# RS14100 register map
File version: 1.0
CPU: CM4 r0p1, little endian, MPU, FPU, 4 interrupt priority bits
Registers are 32-bit, read-write, reset 0x0 unless marked. A register's access mark holds for its fields unless they carry their own. Offsets are from the block's base; [hi:lo] are bit positions; {n}, {i} and the like mark numbered series.

## ETHERNET — Ether MAC 10/100/1000 Universal enables a host to transmit and receive data over Ethernet in compliance with the IEEE 802.3-2002 standard
Base 0x20240000
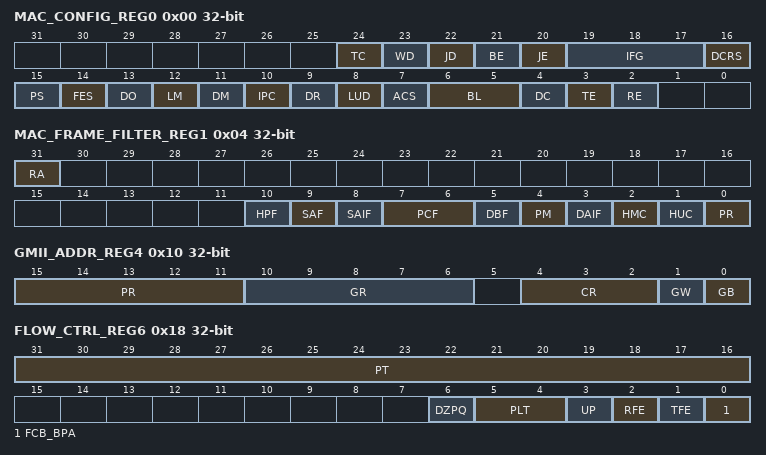
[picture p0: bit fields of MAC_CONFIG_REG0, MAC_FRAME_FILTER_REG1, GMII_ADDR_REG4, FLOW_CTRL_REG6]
0x00 MAC_CONFIG_REG0 — This is the operation mode register for the MAC.
  [24] TC — Transmit Configuration in RGMII/SGMII
  [23] WD — Watchdog Disable When this bit is set, the GMAC disables the watchdog timer on the receiver, and can receive frames of up to 16,384 bytes
  [22] JD — Jabber Disable
  [21] BE — Frame Burst Enable
  [20] JE — Jumbo Frame Enable
  [19:17] IFG — Inter-Frame Gap These bits control the minimum IFG between frames during transmission
  [16] DCRS — Disable Carrier Sense During Transmission
  [15] PS — Selects between GMII and MII:
    1=enable (1: MII (10/100 Mbps)); 0=disable (0: GMII (1000 Mbps))
  [14] FES — Indicates the speed in Fast Ethernet (MII) mode:
    1=enable (100Mbps); 0=disable (10Mbps)
  [13] DO — Disable Receive Own
  [12] LM — Loop-back Mode
  [11] DM — Duplex Mode
  [10] IPC — Checksum Offload
  [9] DR — Disable Retry
  [8] LUD — Link Up/Down
    1=enable (Link Up); 0=disable (Link Down)
  [7] ACS — Automatic Pad/CRC Stripping
  [6:5] BL — Back-Off Limit
  [4] DC — Deferral Check
  [3] TE — Transmitter Enable
  [2] RE — Receiver Enable
0x04 MAC_FRAME_FILTER_REG1 — This is the operation mode register for the MAC.
  [31] RA — Receive All
  [10] HPF — Hash or Perfect Filter
  [9] SAF — Source Address Filter Enable
  [8] SAIF — SA Inverse Filtering
  [7:6] PCF — Pass Control Frames
  [5] DBF — Disable Broadcast Frames
  [4] PM — Pass All Multicast
  [3] DAIF — DA Inverse Filtering
  [2] HMC — Hash Multicast
  [1] HUC — Hash Unicast
  [0] PR — Promiscuous Mode
0x08 HASH_TABLE_HIGH_REG2 — This is the operation mode register for the MAC.
  [31:0] HTH — Hash Table High This field contains the upper 32 bits of Hash table.
0x0C HASH_TABLE_LOW_REG3 — This is the operation mode register for the MAC.
  [31:0] HTL — Hash Table Low This field contains the lower 32 bits of Hash table.
0x10 GMII_ADDR_REG4 — This is the operation mode register for the MAC.
  [15:11] PR — Physical Layer Address This field tells which of the 32 possible PHY devices are being accessed
  [10:6] GR — GMII Register These bits select the desired GMII register in the selected PHY device
  [4:2] CR — CSR Clock Range. The CSR Clock Range selection determines the clk_csr_i frequency and is used to decide the frequency of the MDC clock
  [1] GW — GMII Write. When set this bit tells the PHY that this will be a Write operation using the GMII Data register
  [0] GB — GMII Busy
0x14 GMII_DATA_REG5 — This is the operation mode register for the MAC.
  [15:0] GD — GMII Data.This contains the 16-bit data value read from the PHY after a Management Read operation or the 16-bit data value to be written to the PHY before a Management Write operation
0x18 FLOW_CTRL_REG6 — The Flow Control register controls the generation and reception of the Control (Pause Command) frames by the GMAC's Flow control module.
  [31:16] PT — Pause Time
  [6] DZPQ — Disable Zero-Quanta Pause
  [5:4] PLT — Pause Low Threshold
    0=Pause time 4 slot times; 1=Pause time 28 slot times; 2=Pause time 144 slot times; 3=Pause time 256 slot times
  [3] UP — Unicast Pause Frame Detect
  [2] RFE — Receive Flow Control Enable
  [1] TFE — Transmit Flow Control Enable
  [0] FCB_BPA — Flow Control Busy/Back pressure Activate
0x1C VLAN_TAG_REG7 — The Flow Control register controls the generation and reception of the Control (Pause Command) frames by the GMAC's Flow control module.
  [15:0] VL — VLAN Tag Identifier.This contains the 802.1Q VLAN Tag to identify the VLAN frames, and is used to compare with the 15th and 16th bytes of the receiving frames for VLAN frames
0x20 VERSION_REG8 ro reset 0x33 — The Version register s contents identify the version of the core.
0x28 RMT_WKUP_FMFILTER_REG — This is the address through which the remote Wake-up Frame Filter registers (wkupfmfilter_reg) are written/read by the Application. This register contains the higher 16 bits of the 7th MAC address.
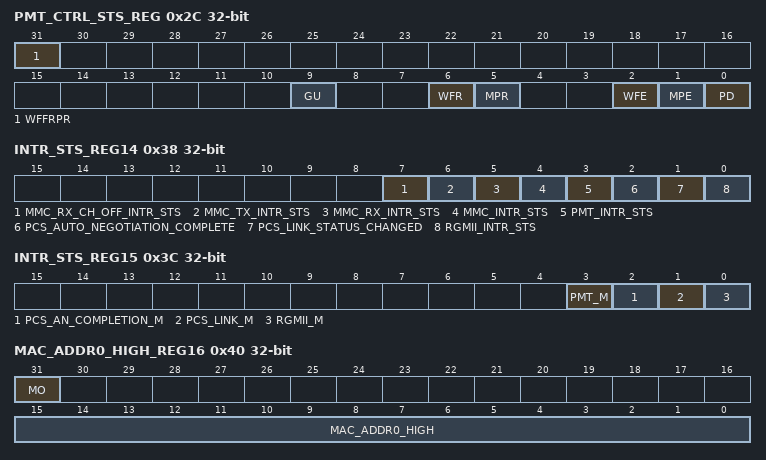
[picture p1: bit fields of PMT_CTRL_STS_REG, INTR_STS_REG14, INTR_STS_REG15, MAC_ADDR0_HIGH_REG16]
0x2C PMT_CTRL_STS_REG — The PMT CSR program the request wake-up events and monitor the wake-up events.
  [31] WFFRPR — When set, resets the Remote Wake-up Frame Filter register pointer to 000
  [9] GU — When set, enables any unicast packet filtered by the GMAC (DAF) address recognition to be a wake-up frame
  [6] WFR — When set, this bit indicates the power management event was generated due to reception of a wake-up frame
  [5] MPR — When set, this bit indicates the power management event was generated by the reception of a Magic Packet
  [2] WFE — Wake-Up Frame Enable.When set, enables generation of a power management event due to wakeup frame reception
  [1] MPE — Magic Packet Enable.When set, enables generation of a power management event due to Magic Packet reception
  [0] PD — When set, all received frames will be dropped
0x38 INTR_STS_REG14 ro — The Interrupt Status register contents identify the events in the GMAC-CORE that can generate interrupt
  [7] MMC_RX_CH_OFF_INTR_STS — MMC Receive Checksum Offload Interrupt Status
  [6] MMC_TX_INTR_STS — MMC Transmit Interrupt Status
  [5] MMC_RX_INTR_STS — MMC Receive Interrupt Status
  [4] MMC_INTR_STS — This bit is set high whenever any of bits 7:5 is set high and cleared only when all of these bits are low.
  [3] PMT_INTR_STS — This bit is set when the Auto-negotiation is completed in the TBI/RTBI/SGMII PHY interface
  [2] PCS_AUTO_NEGOTIATION_COMPLETE — This bit is set when the Auto-negotiation is completed in the TBI/RTBI/SGMII PHY interface
  [1] PCS_LINK_STATUS_CHANGED — This bit is set due to any change in Link Status in the TBI/RTBI/SGMII PHY interface
  [0] RGMII_INTR_STS — This bit is set due to any change in value of the Link Status of RGMII interface
0x3C INTR_STS_REG15 — The Interrupt Mask Register bits enables the user to mask the interrupt signal due to the corresponding event in the Interrupt Status Register
  [3] PMT_M — This bit when set, will disable the assertion of the interrupt signal due to the setting of PMT Interrupt Status bit in Register14
  [2] PCS_AN_COMPLETION_M — This bit when set, will disable the assertion of the interrupt signal due to the setting of RGMII Interrupt Status bit in Register14.
  [1] PCS_LINK_M — This bit when set, will disable the assertion of the interrupt signal due to the setting of RGMII Interrupt Status bit in Register14.
  [0] RGMII_M — This bit when set, will disable the assertion of the interrupt signal due to the setting of RGMII Interrupt Status bit in Register14.
0x40 MAC_ADDR0_HIGH_REG16 — The MAC Address0 High register holds the upper 16 bits of the 6-byte first MAC address of the station
  [31] MO ro — Always 1
  [15:0] MAC_ADDR0_HIGH — This field contains the upper 16 bits (47:32) of the 6-byte first MAC address
0x44 MAC_ADDR0_LOW_REG17 — The MAC Address0 Low register holds the lower 32 bits of the 6-byte first MAC address of the station
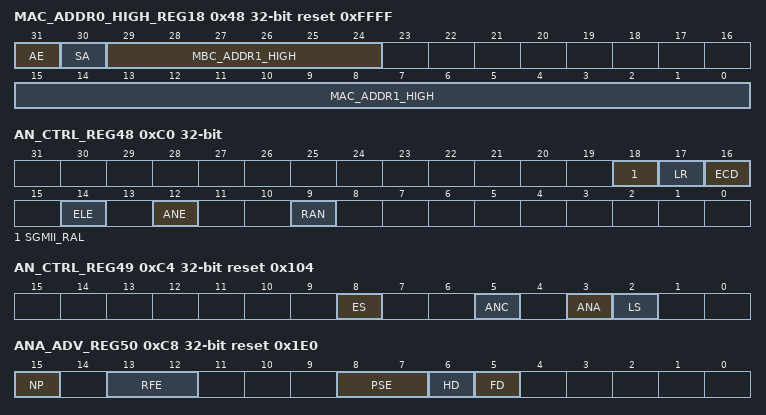
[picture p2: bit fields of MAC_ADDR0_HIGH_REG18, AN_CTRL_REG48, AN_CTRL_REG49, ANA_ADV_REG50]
0x48 MAC_ADDR0_HIGH_REG18 reset 0xFFFF — The MAC Address1 High register holds the upper 16 bits of the 6-byte second MAC address of the station.
  [31] AE — When this bit is set, the Address filter module uses the second MAC address for perfect filtering
  [30] SA — When this bit is set, the MAC Address1[47:0] is used to compare with the SA fields of the received frame
  [29:24] MBC_ADDR1_HIGH — Mask Byte Control
  [15:0] MAC_ADDR1_HIGH — This field contains the upper 16 bits (47:32) of the 6-byte second MAC address.
0x4C MAC_ADDR0_LOW_REG19 reset 0xFFFFFFFF — The MAC Address1 Low register holds the lower 32 bits of the 6-byte second MAC address of the station
  [31:0] MAC_ADDR1_LOW — This field contains the upper 16 bits (47:32) of the 6-byte second MAC address.
0xC0 AN_CTRL_REG48 — The AN Control register enables and/or restarts auto-negotiation.
  [18] SGMII_RAL — SGMII RAL Control
  [17] LR — Enable Comma Detect
  [16] ECD — Enable Comma Detect
  [14] ELE — External Loopback Enable
  [12] ANE — Auto-Negotiation Enable
  [9] RAN — Restart Auto-Negotiation
0xC4 AN_CTRL_REG49 ro reset 0x104 — The AN Status register indicates the link and the auto-negotiation status
  [8] ES — Extended Status
  [5] ANC — Auto-Negotiation Complete
  [3] ANA — Auto-Negotiation Ability
  [2] LS — Link Status
0xC8 ANA_ADV_REG50 reset 0x1E0 — The Auto-Negotiation Advertisement register indicates the link and the auto-negotiation status.
  [15] NP ro — Next Page Support
  [13:12] RFE — Remote Fault Encoding
  [8:7] PSE — Pause Encoding
  [6] HD — Half-Duplex
  [5] FD — Full-Duplex.This bit, when set high, indicates that the GMAC supports Full-Duplex.
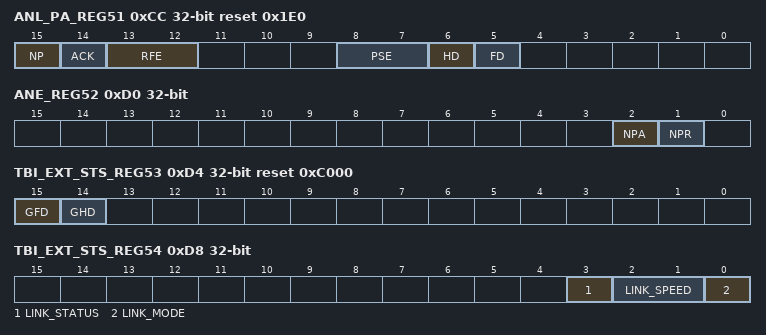
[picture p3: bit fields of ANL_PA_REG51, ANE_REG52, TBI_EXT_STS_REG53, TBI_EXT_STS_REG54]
0xCC ANL_PA_REG51 ro reset 0x1E0 — The Auto-Negotiation Link Partner Ability register contains the advertised ability of the link partner
  [15] NP — Next Page Support
  [14] ACK — Acknowledge
  [13:12] RFE — Remote Fault Encoding
  [8:7] PSE — Pause Encoding
  [6] HD — Half-Duplex
  [5] FD — Full-Duplex.This bit, when set high, indicates that the GMAC supports Full-Duplex.
0xD0 ANE_REG52 ro — The Auto-Negotiation Expansion register indicates whether a new base page from the link partner has been received
  [2] NPA — Next Page Ability
  [1] NPR — New Page Received
0xD4 TBI_EXT_STS_REG53 ro reset 0xC000 — The TBI Extended Status Register register indicates all modes of operation of the GMAC.
  [15] GFD — 1000BASE-X Full-Duplex Capable
  [14] GHD — 1000BASE-X Half-Duplex Capable
0xD8 TBI_EXT_STS_REG54 ro — The SGMII/RGMII Status register indicates the status signals received by the SGMII/RGMII from the PHY
  [3] LINK_STATUS — Indicates whether the link is up 1 or down 0.
  [2:1] LINK_SPEED — Indicates the current speed of the link:
  [0] LINK_MODE — Indicates the current mode of operation of the link
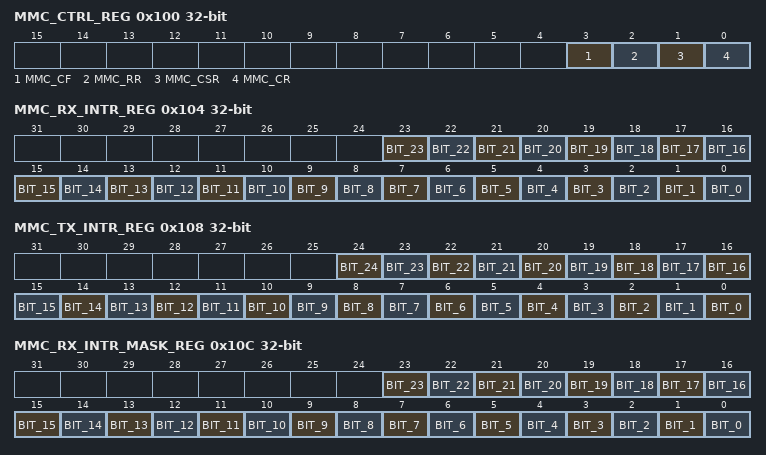
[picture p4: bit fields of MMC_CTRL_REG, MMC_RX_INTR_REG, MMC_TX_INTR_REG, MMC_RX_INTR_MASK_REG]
0x100 MMC_CTRL_REG — The MMC Control register establishes the operating mode of the management counters.
  [3] MMC_CF — MMC Counter Freeze.When set, this bit freezes all the MMC counters to their current value.
  [2] MMC_RR — Reset on Read. When set, counter after reaching maximum value will not roll over to zero.
  [1] MMC_CSR — Counter Stop Roll over.When set, counter after reaching maximum value will not roll over to zero.
  [0] MMC_CR — Counters Reset.When set, all counters will be reset. This bit will be cleared automatically after 1 clock cycle
0x104 MMC_RX_INTR_REG ro — The MMC Receive Interrupt register maintains the interrupts generated when receive statistic counters reach half their maximum values
  [23] BIT_23 — The bit is set when the rx watchdog error counter reaches half the maximum value.
  [22] BIT_22 — The bit is set when the rxvlanframes_gb counter reaches half the maximum value.
  [21] BIT_21 — The bit is set when the rx fifo overflow counter reaches half the maximum value.
  [20] BIT_20 — The bit is set when the rx pause frames counter reaches half the maximum value
  [19] BIT_19 — The bit is set when the rx out of range type counter reaches half the maximum value
  [18] BIT_18 — The bit is set when the rx length error counter reaches half the maximum value.
  [17] BIT_17 — The bit is set when the rxunicastframes_gb counter reaches half the maximum value.
  [16] BIT_16 — The bit is set when the rx1024tomaxoctets_gb counter reaches half the maximum value.
  [15] BIT_15 — The bit is set when the rx512to1023octets_gb counter reaches half the maximum value.
  [14] BIT_14 — The bit is set when the rx256to511octets_gb counter reaches half the maximum value
  [13] BIT_13 — The bit is set when the rx128to255octets_gb counter reaches half the maximum value.
  [12] BIT_12 — The bit is set when the rx65to127octets_gb counter reaches half the maximum value.
  [11] BIT_11 — The bit is set when the rx64octets_gb counter reaches half the maximum value.
  [10] BIT_10 — The bit is set when the rxoversize_g counter reaches half the maximum value.
  [9] BIT_9 — The bit is set when the rxundersize_g counter reaches half the maximum value.
  [8] BIT_8 — The bit is set when the rxjabbererror counter reaches half the maximum value.
  [7] BIT_7 — The bit is set when the rxrunterror counter reaches half the maximum value.
  [6] BIT_6 — The bit is set when the rxalignmenterror counter reaches half the maximum value
  [5] BIT_5 — The bit is set when the rxcrcerror counter reaches half the maximum value.
  [4] BIT_4 — The bit is set when the rxmulticastframes_g counter reaches half the maximum value.
  [3] BIT_3 — The bit is set when the rxbroadcastframes_g counter reaches half the maximum value
  [2] BIT_2 — The bit is set when the rxoctetcount_g counter reaches half the maximum value.
  [1] BIT_1 — The bit is set when the rxoctetcount_gb counter reaches half the maximum value.
  [0] BIT_0 — The bit is set when the rx framecount_gb counter reaches half the maximum value
0x108 MMC_TX_INTR_REG ro — The MMC Transmit Interrupt register maintains the interrupts generated when transmit statistic counters reach half their maximum values
  [24] BIT_24 — The bit is set when the txvlanframes_g counter reaches half the maximum value
  [23] BIT_23 — The bit is set when the tx pause frames error counter reaches half the maximum value.
  [22] BIT_22 — The bit is set when the txoexcessdef counter reaches half the maximum value
  [21] BIT_21 — The bit is set when the txframecount_g counter reaches half the maximum value.
  [20] BIT_20 — The bit is set when the txoctetcount_g counter reaches half the maximum value
  [19] BIT_19 — The bit is set when the txcarriererror counter reaches half the maximum value
  [18] BIT_18 — The bit is set when the txexesscol counter reaches half the maximum value.
  [17] BIT_17 — The bit is set when the txlatecol counter reaches half the maximum value
  [16] BIT_16 — The bit is set when the txdeferred counter reaches half the maximum value
  [15] BIT_15 — The bit is set when the txmulticol_g counter reaches half the maximum value
  [14] BIT_14 — The bit is set when the txsinglecol_g counter reaches half the maximum value
  [13] BIT_13 — The bit is set when the txunderflowerror counter reaches half the maximum value.
  [12] BIT_12 — The bit is set when the txbroadcastframes_gb counter reaches half the maximum value
  [11] BIT_11 — The bit is set when the txmulticastframes_gb counter reaches half the maximum value.
  [10] BIT_10 — The bit is set when the txunicastframes_gb counter reaches half the maximum value.
  [9] BIT_9 — The bit is set when the tx1024tomaxoctets_gb counter reaches half the maximum value
  [8] BIT_8 — The bit is set when the tx512to1023octets_gb counter reaches half the maximum value
  [7] BIT_7 — The bit is set when the tx256to511octets_gb counter reaches half the maximum value.
  [6] BIT_6 — The bit is set when the tx128to255octets_gb counter reaches half the maximum value.
  [5] BIT_5 — The bit is set when the tx65to127octets_gb counter reaches half the maximum value
  [4] BIT_4 — The bit is set when the tx64to127octets_gb counter reaches half the maximum value.
  [3] BIT_3 — The bit is set when the txmulticastframes_g counter reaches half the maximum value.
  [2] BIT_2 — The bit is set when the txbroadcastframes_g counter reaches half the maximum value.
  [1] BIT_1 — The bit is set when the txframecount_gb counter reaches half the maximum value.
  [0] BIT_0 — The bit is set when the txoctetcount_gb counter reaches half the maximum value.
0x10C MMC_RX_INTR_MASK_REG — MMC Receive Interrupt Mask register maintains the masks for the interrupts generated when receive statistic counters reach half their maximum value
  [23] BIT_23 ro — Setting this bit masks the interrupt when the rxframecount_gb counter reaches half the maximum value
  [22] BIT_22 ro — Setting this bit masks the interrupt when the rxvlanframes_gb counter reaches half the maximum value
  [21] BIT_21 ro — Setting this bit masks the interrupt when the rxfifooverflow counter reaches half the maximum value
  [20] BIT_20 ro — Setting this bit masks the interrupt when the rxpauseframes counter reaches half the maximum value
  [19] BIT_19 ro — Setting this bit masks the interrupt when the rx out of range type counter reaches half the maximum value
  [18] BIT_18 ro — Setting this bit masks the interrupt when the rx length error counter reaches half the maximum value.
  [17] BIT_17 ro — Setting this bit masks the interrupt when the rxunicastframes_gb counter reaches half the maximum value.
  [16] BIT_16 ro — Setting this bit masks the interrupt when the rx1024tomaxoctets_gb counter reaches half the maximum value.
  [15] BIT_15 ro — Setting this bit masks the interrupt when the rx512to1023octets_gb counter reaches half the maximum value.
  [14] BIT_14 ro — Setting this bit masks the interrupt when the rx256to511octets_gb counter reaches half the maximum value
  [13] BIT_13 ro — Setting this bit masks the interrupt when the rx128to255octets_gb counter reaches half the maximum value.
  [12] BIT_12 ro — Setting this bit masks the interruptwhen the rx65to127octets_gb counter reaches half the maximum value.
  [11] BIT_11 ro — Setting this bit masks the interrupt when the rx64octets_gb counter reaches half the maximum value.
  [10] BIT_10 ro — The bit is set when the rxoversize_g counter reaches half the maximum value.
  [9] BIT_9 ro — Setting this bit masks the interrupt when the rxundersize_g counter reaches half the maximum value.
  [8] BIT_8 ro — Setting this bit masks the interrupt when the rxjabbererror counter reaches half the maximum value.
  [7] BIT_7 ro — Setting this bit masks the interrupt when the rxrunterror counter reaches half the maximum value.
  [6] BIT_6 ro — The bit is set when the rxalignmenterror counter reaches half the maximum value
  [5] BIT_5 ro — Setting this bit masks the interrupt when the rxcrcerror counter reaches half the maximum value.
  [4] BIT_4 ro — The bit is set when the rxmulticastframes_g counter reaches half the maximum value.
  [3] BIT_3 ro — Setting this bit masks the interrupt when the rxbroadcastframes_g counter reaches half the maximum value
  [2] BIT_2 ro — Setting this bit masks the interrupt when the rxoctetcount_g counter reaches half the maximum value.
  [1] BIT_1 ro — Setting this bit masks the interrupt when the rxoctetcount_gb counter reaches half the maximum value
  [0] BIT_0 ro — Setting this bit masks the interrupt when the rxframecount_gb counter reaches half the maximum value
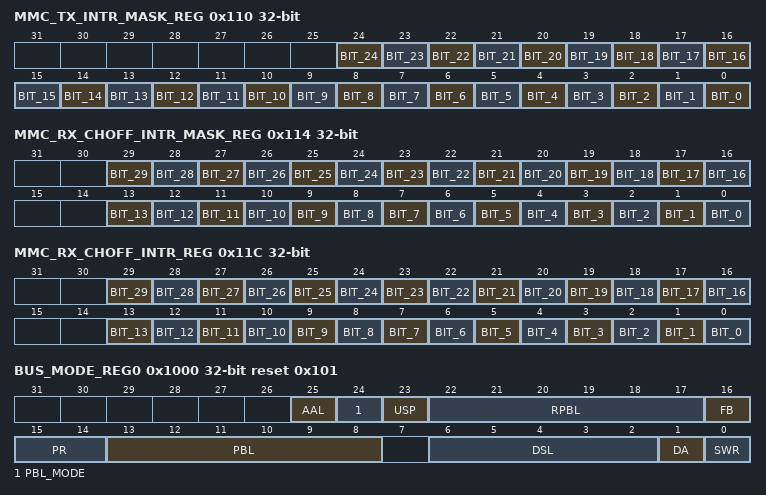
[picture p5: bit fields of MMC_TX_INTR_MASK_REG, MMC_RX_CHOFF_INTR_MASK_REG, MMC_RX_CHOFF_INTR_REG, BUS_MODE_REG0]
0x110 MMC_TX_INTR_MASK_REG — The MMC Transmit Interrupt Mask register maintains the masks for the interrupts generated when transmit statistic counters reach half their maximum value
  [24] BIT_24 ro — Setting this bit masks the interrupt when the txvlanframes_g counter reaches half the maximum value.
  [23] BIT_23 ro — Setting this bit masks the interrupt when the txpauseframes counter reaches half the maximum value.
  [22] BIT_22 ro — Setting this bit masks the interrupt when the txoexcessdef counter reaches half the maximum value.
  [21] BIT_21 ro — Setting this bit masks the interrupt when the txframecount_g counter reaches half the maximum value.
  [20] BIT_20 ro — Setting this bit masks the interrupt when the txoctetcount_g counter reaches half the maximum value
  [19] BIT_19 ro — Setting this bit masks the interrupt when the txcarriererror counter reaches half the maximum value
  [18] BIT_18 ro — Setting this bit masks the interrupt when the txexesscol counter reaches half the maximum value.
  [17] BIT_17 ro — Setting this bit masks the interrupt when the txlatecol counter reaches half the maximum value
  [16] BIT_16 ro — Setting this bit masks the interrupt when the txdeferred counter reaches half the maximum value
  [15] BIT_15 ro — Setting this bit masks the interrupt when the txmulticol_g counter reaches half the maximum value
  [14] BIT_14 ro — Setting this bit masks the interrupt when the txsinglecol_g counter reaches half the maximum value
  [13] BIT_13 ro — Setting this bit masks the interrupt when the txunderflowerror counter reaches half the maximum value.
  [12] BIT_12 ro — Setting this bit masks the interrupt when the txbroadcastframes_gb counter reaches half the maximum value
  [11] BIT_11 ro — Setting this bit masks the interrupt when the txmulticastframes_gb counter reaches half the maximum value.
  [10] BIT_10 ro — Setting this bit masks the interrupt when the txunicastframes_gb counter reaches half the maximum value.
  [9] BIT_9 ro — Setting this bit masks the interrupt when the tx1024tomaxoctets_gb counter reaches half the maximum value
  [8] BIT_8 ro — Setting this bit masks the interrupt when the tx512to1023octets_gb counter reaches half the maximum value
  [7] BIT_7 ro — Setting this bit masks the interrupt when the tx256to511octets_gb counter reaches half the maximum value.
  [6] BIT_6 ro — Setting this bit masks the interrupt when the tx128to255octets_gb counter reaches half the maximum value.
  [5] BIT_5 ro — Setting this bit masks the interrupt when the tx65to127octets_gb counter reaches half the maximum value
  [4] BIT_4 ro — Setting this bit masks the interrupt when the tx64to127octets_gb counter reaches half the maximum value.
  [3] BIT_3 ro — Setting this bit masks the interrupt when the txmulticastframes_g counter reaches half the maximum value.
  [2] BIT_2 ro — Setting this bit masks the interrupt when the txbroadcastframes_g counter reaches half the maximum value.
  [1] BIT_1 ro — Setting this bit masks the interrupt when the txframecount_gb counter reaches half the maximum value
  [0] BIT_0 ro — Setting this bit masks the interrupt when the txoctetcount_gb counter reaches half the maximum value
0x114 MMC_RX_CHOFF_INTR_MASK_REG — The MMC Receive Checksum Offload Interrupt Mask register maintains the masks for the interrupts generated when the receive IPC (Checksum Offload) statistic counters reach half their maximum value
  [29] BIT_29 — Setting this bit masks the interrupt when the rxicmp_err_octets counter reaches half the maximum value.
  [28] BIT_28 — Setting this bit masks the interrupt when the rxicmp_gd_octets counter reaches half the maximum value
  [27] BIT_27 — Setting this bit masks the interrupt when the rxtcp_err_octets counter reaches half the maximum value.
  [26] BIT_26 — Setting this bit masks the interrupt when the rxtcp_gd_octets counter reaches half the maximum value.
  [25] BIT_25 — Setting this bit masks the interrupt when the rxudp_err_octets counter reaches half the maximum value
  [24] BIT_24 — Setting this bit masks the interrupt when the rxudp_gd_octets counter reaches half the maximum value.
  [23] BIT_23 — Setting this bit masks the interrupt when the rxipv6_nopay_octets counter reaches half the maximum value
  [22] BIT_22 — Setting this bit masks the interrupt when the rxipv6_hdrerr_octets counter reaches half the maximum value.
  [21] BIT_21 — Setting this bit masks the interrupt when the rxipv6_gd_octets counter reaches half the maximum value.
  [20] BIT_20 — Setting this bit masks the interrupt when the rxipv4_udsbl_octets counter reaches half the maximum value.
  [19] BIT_19 — Setting this bit masks the interrupt when the rxipv4_frag_octets counter reaches half the maximum value
  [18] BIT_18 — Setting this bit masks the interrupt when the rxipv4_nopay_octets counter reaches half the maximum value.
  [17] BIT_17 — Setting this bit masks the interrupt when the rxipv4_hdrerr_octets counter reaches half the maximum value.
  [16] BIT_16 — Setting this bit masks the interrupt when the rxipv4_gd_octets counter reaches half the maximum value
  [13] BIT_13 — Setting this bit masks the interrupt when the rxicmp_err_frms counter reaches half the maximum value.
  [12] BIT_12 — Setting this bit masks the interrupt when the rxicmp_gd_frms counter reaches half the maximum value
  [11] BIT_11 — Setting this bit masks the interrupt when the rxtcp_err_frms counter reaches half the maximum value
  [10] BIT_10 — Setting this bit masks the interrupt when the rxtcp_gd_frms counter reaches half the maximum value
  [9] BIT_9 — Setting this bit masks the interrupt when the rxudp_err_frms counter reaches half the maximum value
  [8] BIT_8 — Setting this bit masks the interrupt when the rxudp_gd_frms counter reaches half the maximum value
  [7] BIT_7 — Setting this bit masks the interrupt when the rxipv6_nopay_frms counter reaches half the maximum value.
  [6] BIT_6 — Setting this bit masks the interrupt when the rxipv6_hdrerr_frms counter reaches half the maximum value
  [5] BIT_5 — Setting this bit masks the interrupt when the rxipv6_gd_frms counter reaches half the maximum value
  [4] BIT_4 — Setting this bit masks the interrupt when the rxipv4_udsbl_frms counter reaches half the maximum value
  [3] BIT_3 — Setting this bit masks the interrupt when the rxipv4_frag_frms counter reaches half the maximum value
  [2] BIT_2 — Setting this bit masks the interrupt when the rxipv4_gd_frms counter reaches half the maximum value.
  [1] BIT_1 — Setting this bit masks the interrupt when the rxipv4_gd_frms counter reaches half the maximum value.
  [0] BIT_0 — Setting this bit masks the interrupt when the rxipv4_gd_frms counter reaches half the maximum value.
0x11C MMC_RX_CHOFF_INTR_REG ro — The MMC Receive Checksum Offload Interrupt register maintains the interrupts generated when receive IPC statistic counters reach half their maximum values
  [29] BIT_29 — The bit is set when the rxicmp_err_octets counter reaches half the maximum value.
  [28] BIT_28 — The bit is set when the rxicmp_gd_octets counter reaches half the maximum value
  [27] BIT_27 — The bit is set when the rxtcp_err_octets counter reaches half the maximum value.
  [26] BIT_26 — The bit is set when the rxtcp_gd_octets counter reaches half the maximum value.
  [25] BIT_25 — The bit is set when the rxudp_err_octets counter reaches half the maximum value
  [24] BIT_24 — The bit is set when the rxudp_gd_octets counter reaches half the maximum value.
  [23] BIT_23 — The bit is set when the rxipv6_nopay_octets counter reaches half the maximum value.
  [22] BIT_22 — The bit is set when the rxipv6_hdrerr_octets counter reaches half the maximum value.
  [21] BIT_21 — The bit is set when the rxipv6_gd_octets counter reaches half the maximum value.
  [20] BIT_20 — The bit is set when the rxipv4_udsbl_octets counter reaches half the maximum value.
  [19] BIT_19 — The bit is set when the rxipv4_frag_octets counter reaches half the maximum value.
  [18] BIT_18 — The bit is set when the rxipv4_nopay_octets counter reaches half the maximum value
  [17] BIT_17 — The bit is set when the rxipv4_hdrerr_octets counter reaches half the maximum value.
  [16] BIT_16 — The bit is set when the rxipv4_gd_octets counter reaches half the maximum value
  [13] BIT_13 — The bit is set when the rxicmp_err_frms counter reaches half the maximum value.
  [12] BIT_12 — The bit is set when the rxicmp_gd_frms counter reaches half the maximum value.
  [11] BIT_11 — The bit is set when the rxtcp_err_frms counter reaches half the maximum value.
  [10] BIT_10 — The bit is set when the rxtcp_gd_frms counter reaches half the maximum value
  [9] BIT_9 — The bit is set when the rxudp_err_frms counter reaches half the maximum value
  [8] BIT_8 — The bit is set when the rxudp_gd_frms counter reaches half the maximum value
  [7] BIT_7 — The bit is set when the rxipv6_nopay_frms counter reaches half the maximum value
  [6] BIT_6 — The bit is set when the rxipv6_hdrerr_frms counter reaches half the maximum value.
  [5] BIT_5 — The bit is set when the rxipv6_gd_frms counter reaches half the maximum value
  [4] BIT_4 — The bit is set when the rxipv4_udsbl_frms counter reaches half the maximum value
  [3] BIT_3 — The bit is set when the rxipv4_frag_frms counter reaches half the maximum value
  [2] BIT_2 — The bit is set when the rxipv4_nopay_frms counter reaches half the maximum value.
  [1] BIT_1 — The bit is set when the rxipv4_hdrerr_frms counter reaches half the maximum value.
  [0] BIT_0 — The bit is set when the rxipv4_gd_frms counter reaches half the maximum value
0x1000 BUS_MODE_REG0 reset 0x101 — The Bus Mode register establishes the bus operating modes for the DMA.
  [25] AAL — Address-Aligned Beats
  [24] PBL_MODE — When set high, this bit multiplies the PBL value programmed four times
  [23] USP — Use Separate PBL
  [22:17] RPBL — RxDMA PBL
  [16] FB — Fixed Burst
  [15:14] PR — Rx:Tx priority ratio
    {v}={v+1}:1 (v=0..3)
  [13:8] PBL — Programmable Burst Length.These bits indicate the maximum number of beats to be transferred in one DMA transaction
  [6:2] DSL — Descriptor Skip Length
  [1] DA — DMA Arbitration scheme
    1=enable (Rx has priority over Tx); 0=disable (Round-robin with Rx:Tx priority given in bits 15:14)
  [0] SWR — Software Reset
0x1004 TX_POLL_DEMAND_REG1 — The Transmit Poll Demand register enables the Transmit DMA to check whether or not the current descriptor is owned by DMA
  [31:0] TPD — Transmit Poll Demand
0x1008 RX_POLL_DEMAND_REG — The Receive Poll Demand register enables the receive DMA to check for new descriptors
  [31:0] RPD — Receive Poll Demand
0x100C RC_DESC_LIST_ADDR_REG3 — The Receive Descriptor List Address register points to the start of the Receive Descriptor List
  [31:0] START_RX_LIST — This field contains the base address of the First Descriptor in the Receive Descriptor list.
0x1010 TX_DESC_LIST_ADDR_REG4 — The Receive Descriptor List Address register points to the start of the Receive Descriptor List
  [31:0] START_TX_LIST — This field contains the base address of the First Descriptor in the Transmit Descriptor list.
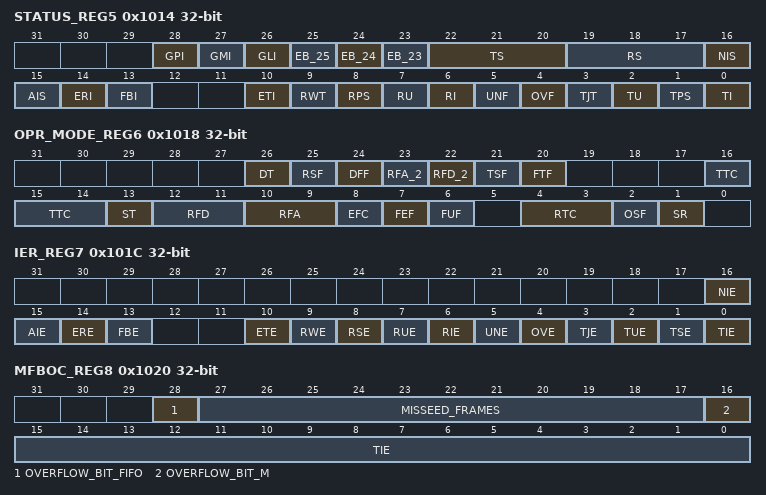
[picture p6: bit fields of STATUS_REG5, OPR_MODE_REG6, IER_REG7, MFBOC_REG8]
0x1014 STATUS_REG5 — The Status register contains all the status bits that the DMA reports to the host
  [28] GPI ro — GMAC PMT Interrupt
  [27] GMI ro — GMAC MMC Interrupt
  [26] GLI ro — GMAC Line interface Interrupt
  [25] EB_25 ro — Error Bits.These bits indicate the type of error that caused a Bus Error
    1=enable (Error during descriptor access); 0=disable (Error during data buffer access)
  [24] EB_24 ro — Error Bits.These bits indicate the type of error that caused a Bus Error
    1=enable (Error during read transfer); 0=disable (Error during write transfer)
  [23] EB_23 ro — Error Bits.These bits indicate the type of error that caused a Bus Error
    1=enable (Error during data transfer by TxDMA); 0=disable (Error during data transfer by RxDMA)
  [22:20] TS ro — Transmit Process State
  [19:17] RS ro — Receive Process State
  [16] NIS — Normal Interrupt Summary
  [15] AIS — Abnormal Interrupt Summary
  [14] ERI — Early Receive Interrupt
  [13] FBI — Fatal Bus Error Interrupt
  [10] ETI — Early Transmit Interrupt
  [9] RWT — Receive Watchdog Time out
  [8] RPS — Receive Process Stopped
  [7] RU — Receive Buffer Unavailable
  [6] RI — Receive Interrupt
  [5] UNF — Transmit Underflow
  [4] OVF — Receive Overflow
  [3] TJT — Transmit Jabber Time out
  [2] TU — Transmit Buffer Unavailable
  [1] TPS — Transmit Process Stopped
  [0] TI — Transmit Interrupt.This bit indicates that frame transmission is finished and TDES1 31 is set in the First Descriptor.
0x1018 OPR_MODE_REG6 — The Operation Mode register establishes the Transmit and Receive operating modes and commands
  [26] DT — Disable Dropping of TCP/IP Checksum Error Frames
  [25] RSF — Receive Store and Forward
  [24] DFF — Disable Flushing of Received Frames
  [23] RFA_2 — MSB of Threshold for Activating Flow Control
  [22] RFD_2 — MSB of Threshold for Deactivating Flow Control
  [21] TSF — Transmit Store and Forward
  [20] FTF — When this bit is set, the transmit FIFO controller logic is reset to its default values and thus all data in the Tx FIFO is lost/flushed
  [16:14] TTC — Transmit Threshold Control
  [13] ST — Start/Stop Transmission Command
  [12:11] RFD — Threshold for deactivating flow control
    {v}=Full {v+1} KB (v=0..3)
  [10:9] RFA — Threshold for activating flow control
    {v}=Full {v+1} KB (v=0..3)
  [8] EFC — Enable HW flow control
  [7] FEF — Forward Error Frames
  [6] FUF — Forward Undersized Good Frames
  [4:3] RTC ro — Receive Threshold Control.These two bits control the threshold level of the MTL Receive FIFO.
    0=64; 1=32; 2=96; 3=128
  [2] OSF — Operate on Second Frame
  [1] SR — Start/Stop Receive
0x101C IER_REG7 — The Interrupt Enable register enables the interrupts reported by Register5
  [16] NIE — Normal Interrupt Summary Enable
  [15] AIE — Abnormal Interrupt Summary Enable
  [14] ERE — Early Receive Interrupt Enable
  [13] FBE — Fatal Bus Error Enable
  [10] ETE — Early Transmit Interrupt Enable
  [9] RWE — Receive Watchdog Time out Enable
  [8] RSE — Receive Stopped Enable
  [7] RUE — Receive Buffer Unavailable Enable
  [6] RIE — Receive Interrupt Enable
  [5] UNE — Underflow Interrupt Enable
  [4] OVE — Overflow Interrupt Enable
  [3] TJE — Transmit Jabber Time out Enable
  [2] TUE — Transmit Buffer Unavailable Enable
  [1] TSE — Transmit Stopped Enable
  [0] TIE — Transmit Interrupt Enable
0x1020 MFBOC_REG8 — The Interrupt Enable register enables the interrupts reported by Register5
  [28] OVERFLOW_BIT_FIFO — Overflow bit for Missed Frame Counter
  [27:17] MISSEED_FRAMES — Indicates the number of frames missed by the application
  [16] OVERFLOW_BIT_M — Overflow bit for Missed Frame Counter
  [15:0] TIE — Indicates the number of frames missed by the controller due to the Host Receive Buffer being unavailable
0x1048 CHTX_DESC_REG18 ro — Host Transmit Descriptor Address Pointer Cleared on Reset. Pointer updated by DMA during operation Buffer being unavailable
0x104C CHRX_DESC_REG19 ro — Host Receive Descriptor Address Pointer Cleared on Reset. Pointer updated by DMA during operation
0x1050 CHRX_DESC_REG20 ro — Host Transmit Buffer Address Pointer Cleared on Reset. Pointer updated by DMA during operation
0x1054 CHRX_BUF_ADDR_REG21 ro — Host Receive Buffer Address Pointer Cleared on Reset. Pointer updated by DMA during operation
